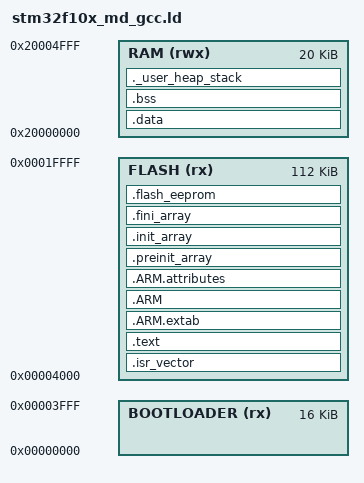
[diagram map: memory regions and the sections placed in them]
/* Linker script for lm3s6730
 *
 * Version:Sourcery G++ 4.2-62
 * BugURL:https://support.codesourcery.com/GNUToolchain/
 *
 *  Copyright 2007 CodeSourcery.
 *
 * The authors hereby grant permission to use, copy, modify, distribute,
 * and license this software and its documentation for any purpose, provided
 * that existing copyright notices are retained in all copies and that this
 * notice is included verbatim in any distributions. No written agreement,
 * license, or royalty fee is required for any of the authorized uses.
 * Modifications to this software may be copyrighted by their authors
 * and need not follow the licensing terms described here, provided that
 * the new terms are clearly indicated on the first page of each file where
 * they apply. */
/*
OUTPUT_FORMAT ("elf32-littlearm", "elf32-bigarm", "elf32-littlearm")

/* Entry Point */
ENTRY(Reset_Handler)

/* Highest address of the user mode stack */
_estack = 0x20005000;    /* end of 20K RAM */

/* Generate a link error if heap and stack don't fit into RAM */
_Min_Heap_Size = 0;      /* required amount of heap  */
_Min_Stack_Size = 0x200; /* required amount of stack */

_Flash_Eeprom_Page_Size = 0x4000;
_Flash_Eeprom_Page_Count = 2;


MEMORY
{
  RAM (rwx) : ORIGIN = 0x20000000, LENGTH = 20K
  BOOTLOADER (rx) : ORIGIN = 0x00000000, LENGTH = 16k
  FLASH (rx) : ORIGIN = 0x00004000, LENGTH = 128K-16k
}
SECTIONS
  {
	/* The startup code goes first into FLASH */
    .isr_vector :
    {
        . = ALIGN(4);
        KEEP(*(.isr_vector)) /* Startup code */
        . = ALIGN(4);
    } > FLASH
    
    /* The program code and other data goes into FLASH */
    .text :
    {
        . = ALIGN(4);
        *(.text)           /* .text sections (code) */
        *(.text*)          /* .text* sections (code) */
        *(.rodata)         /* .rodata sections (constants, strings, etc.) */
        *(.rodata*)        /* .rodata* sections (constants, strings, etc.) */
        *(.glue_7)         /* glue arm to thumb code */
        *(.glue_7t)        /* glue thumb to arm code */

        KEEP (*(.init))
        KEEP (*(.fini))

        . = ALIGN(4);
        _etext = .;        /* define a global symbols at end of code */
     } >FLASH
     
    .ARM.extab   : 
    { 
        *(.ARM.extab* .gnu.linkonce.armextab.*) 
    } >FLASH
    
    .ARM : {
        __exidx_start = .;
        *(.ARM.exidx*)
        __exidx_end = .;
    } >FLASH

    .ARM.attributes : 
    { 
        *(.ARM.attributes) 
    } > FLASH
    
   .preinit_array     :
    {
        PROVIDE_HIDDEN (__preinit_array_start = .);
        KEEP (*(.preinit_array*))
        PROVIDE_HIDDEN (__preinit_array_end = .);
    } >FLASH
    
    .init_array :
    {
        PROVIDE_HIDDEN (__init_array_start = .);
        KEEP (*(SORT(.init_array.*)))
        KEEP (*(.init_array*))
        PROVIDE_HIDDEN (__init_array_end = .);
    } >FLASH
    
    .fini_array :
    {
        PROVIDE_HIDDEN (__fini_array_start = .);
        KEEP (*(.fini_array*))
        KEEP (*(SORT(.fini_array.*)))
        PROVIDE_HIDDEN (__fini_array_end = .);
    } >FLASH
    
    . = ALIGN(_Flash_Eeprom_Page_Size);
    _flash_eeprom_base = .;
    
    . = ALIGN(_Flash_Eeprom_Page_Size);
    .flash_eeprom :
    {
        . = ALIGN(_Flash_Eeprom_Page_Size);
        *(.flash_eeprom) 
    } >FLASH

    /* used by the startup to initialize data */
    . = ALIGN(4);
    _sidata = .;

    /* Initialized data sections goes into RAM, load LMA copy after code */
    .data : AT ( _sidata )
    {
        . = ALIGN(4);
        _sdata = .;        /* create a global symbol at data start */
        *(.data)           /* .data sections */
        *(.data*)          /* .data* sections */

        . = ALIGN(4);
        _edata = .;        /* define a global symbol at data end */
     } >RAM

    /* Uninitialized data section */
    . = ALIGN(4);
    .bss :
    {
    /* This is used by the startup in order to initialize the .bss secion */
        _sbss = .;         /* define a global symbol at bss start */
        __bss_start__ = _sbss;
        *(.bss)
        *(.bss*)
        *(COMMON)

        . = ALIGN(4);
        _ebss = .;         /* define a global symbol at bss end */
        __bss_end__ = _ebss;
    } >RAM

    PROVIDE ( end = _ebss );
    PROVIDE ( _end = _ebss );

    /* User_heap_stack section, used to check that there is enough RAM left */
    ._user_heap_stack :
    {
        . = ALIGN(4);
        . = . + _Min_Heap_Size;
        . = . + _Min_Stack_Size;
        . = ALIGN(4);
    } >RAM

    /* Remove information from the standard libraries */
    /DISCARD/ :
    {
        libc.a ( * )
        libm.a ( * )
        libgcc.a ( * )
    }
}
       
/*========== end of file ==========*/
